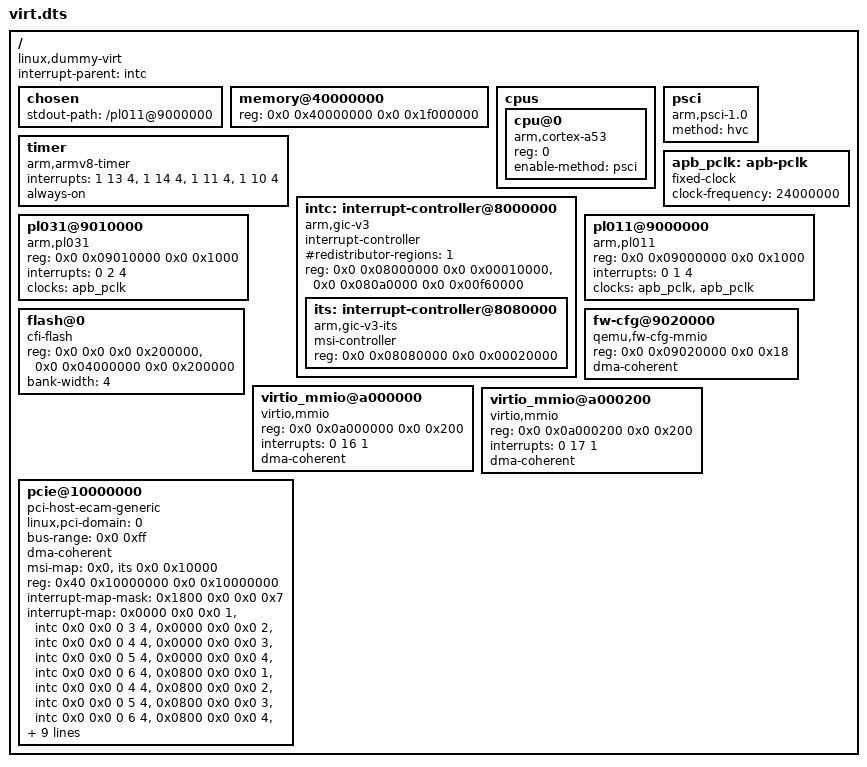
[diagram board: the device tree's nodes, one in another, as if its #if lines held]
/dts-v1/;

/*
 * Guest-visible QEMU virt machine. Compiled with dtc; RAM size is patched
 * at runtime in guest/src/dtb.c.
 *
 * cpp -DVEIL_PCI=1 adds GICv3 ITS + ECAM PCI (qemu-virt host only).
 */

/ {
	compatible = "linux,dummy-virt";
	#address-cells = <2>;
	#size-cells = <2>;
	interrupt-parent = <&intc>;

	chosen {
		stdout-path = "/pl011@9000000";
	};

	memory@40000000 {
		device_type = "memory";
		/* size cell is replaced with platform.guest_ram_size */
		reg = <0x0 0x40000000 0x0 0x1f000000>;
	};

	cpus {
		#address-cells = <1>;
		#size-cells = <0>;

		cpu@0 {
			device_type = "cpu";
			compatible = "arm,cortex-a53";
			reg = <0>;
			enable-method = "psci";
		};
	};

	psci {
		compatible = "arm,psci-1.0", "arm,psci-0.2", "arm,psci";
		method = "hvc";
	};

	timer {
		compatible = "arm,armv8-timer", "arm,armv7-timer";
		interrupts = <1 13 4>, <1 14 4>, <1 11 4>, <1 10 4>;
		always-on;
	};

	intc: interrupt-controller@8000000 {
		compatible = "arm,gic-v3";
		#interrupt-cells = <3>;
		interrupt-controller;
		#address-cells = <2>;
		#size-cells = <2>;
		ranges;
		#redistributor-regions = <1>;
		reg = <0x0 0x08000000 0x0 0x00010000>,
		      <0x0 0x080a0000 0x0 0x00f60000>;

#ifdef VEIL_PCI
		its: interrupt-controller@8080000 {
			compatible = "arm,gic-v3-its";
			msi-controller;
			#msi-cells = <1>;
			reg = <0x0 0x08080000 0x0 0x00020000>;
		};
#endif
	};

	apb_pclk: apb-pclk {
		compatible = "fixed-clock";
		#clock-cells = <0>;
		clock-frequency = <24000000>;
	};

	pl031@9010000 {
		compatible = "arm,pl031", "arm,primecell";
		reg = <0x0 0x09010000 0x0 0x1000>;
		interrupts = <0 2 4>;
		clocks = <&apb_pclk>;
		clock-names = "apb_pclk";
	};

	pl011@9000000 {
		compatible = "arm,pl011", "arm,primecell";
		reg = <0x0 0x09000000 0x0 0x1000>;
		interrupts = <0 1 4>;
		clocks = <&apb_pclk>, <&apb_pclk>;
		clock-names = "uartclk", "apb_pclk";
	};

	flash@0 {
		compatible = "cfi-flash";
		reg = <0x0 0x0 0x0 0x200000>,
		      <0x0 0x04000000 0x0 0x200000>;
		bank-width = <4>;
	};

	fw-cfg@9020000 {
		compatible = "qemu,fw-cfg-mmio";
		reg = <0x0 0x09020000 0x0 0x18>;
		dma-coherent;
	};

	virtio_mmio@a000000 {
		compatible = "virtio,mmio";
		reg = <0x0 0x0a000000 0x0 0x200>;
		interrupts = <0 16 1>;
		dma-coherent;
	};

	virtio_mmio@a000200 {
		compatible = "virtio,mmio";
		reg = <0x0 0x0a000200 0x0 0x200>;
		interrupts = <0 17 1>;
		dma-coherent;
	};

#ifdef VEIL_PCI
	pcie@10000000 {
		compatible = "pci-host-ecam-generic";
		device_type = "pci";
		#address-cells = <3>;
		#size-cells = <2>;
		#interrupt-cells = <1>;
		linux,pci-domain = <0>;
		bus-range = <0x0 0xff>;
		dma-coherent;
		msi-map = <0x0 &its 0x0 0x10000>;
		reg = <0x40 0x10000000 0x0 0x10000000>;
		ranges =
		    <0x01000000 0x0 0x00000000 0x0 0x3eff0000 0x0 0x00010000>,
		    <0x02000000 0x0 0x10000000 0x0 0x10000000 0x0 0x2eff0000>,
		    <0x03000000 0x80 0x00000000 0x80 0x00000000 0x80 0x00000000>;
		interrupt-map-mask = <0x1800 0x0 0x0 0x7>;
		interrupt-map =
		    <0x0000 0x0 0x0 1 &intc 0x0 0x0 0 3 4>,
		    <0x0000 0x0 0x0 2 &intc 0x0 0x0 0 4 4>,
		    <0x0000 0x0 0x0 3 &intc 0x0 0x0 0 5 4>,
		    <0x0000 0x0 0x0 4 &intc 0x0 0x0 0 6 4>,
		    <0x0800 0x0 0x0 1 &intc 0x0 0x0 0 4 4>,
		    <0x0800 0x0 0x0 2 &intc 0x0 0x0 0 5 4>,
		    <0x0800 0x0 0x0 3 &intc 0x0 0x0 0 6 4>,
		    <0x0800 0x0 0x0 4 &intc 0x0 0x0 0 3 4>,
		    <0x1000 0x0 0x0 1 &intc 0x0 0x0 0 5 4>,
		    <0x1000 0x0 0x0 2 &intc 0x0 0x0 0 6 4>,
		    <0x1000 0x0 0x0 3 &intc 0x0 0x0 0 3 4>,
		    <0x1000 0x0 0x0 4 &intc 0x0 0x0 0 4 4>,
		    <0x1800 0x0 0x0 1 &intc 0x0 0x0 0 6 4>,
		    <0x1800 0x0 0x0 2 &intc 0x0 0x0 0 3 4>,
		    <0x1800 0x0 0x0 3 &intc 0x0 0x0 0 4 4>,
		    <0x1800 0x0 0x0 4 &intc 0x0 0x0 0 5 4>;
	};
#endif
};
